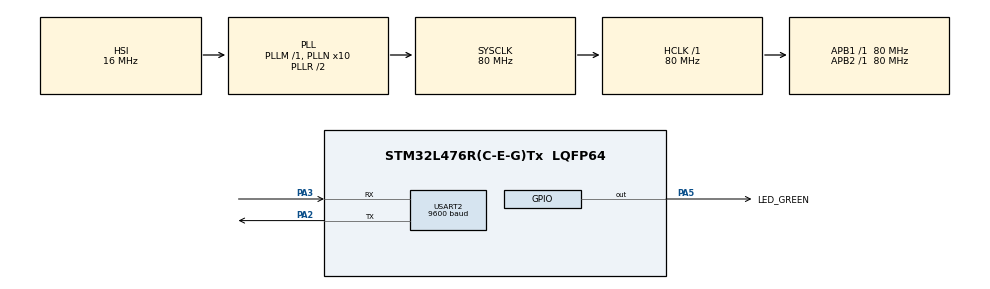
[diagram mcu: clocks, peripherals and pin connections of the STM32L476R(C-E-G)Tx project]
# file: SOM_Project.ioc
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ADC1.Channel-0\#ChannelRegularConversion=ADC_CHANNEL_TEMPSENSOR
ADC1.NbrOfConversionFlag=1
ADC1.OffsetNumber-0\#ChannelRegularConversion=ADC_OFFSET_NONE
ADC1.Rank-0\#ChannelRegularConversion=1
ADC1.SamplingTime-0\#ChannelRegularConversion=ADC_SAMPLETIME_2CYCLES_5
ADC1.master=1
FREERTOS.Queues01=ledCmd,4,Command_t,0,Dynamic,NULL,NULL;adcAnalyzer,16,uint16_t,0,Dynamic,NULL,NULL;adcAlert,16,uint16_t,0,Dynamic,NULL,NULL;uartTx,16,uint8_t,0,Dynamic,NULL,NULL
FREERTOS.Tasks01=UartTask,24,256,StartUartTask,Default,NULL,Dynamic,NULL,NULL;LedTask,8,128,StartLedTask,Default,NULL,Dynamic,NULL,NULL;ADCSampler,8,256,StartADCSampler,Default,NULL,Dynamic,NULL,NULL;DataAnalyzer,8,256,StartDataAnalyzer,Default,NULL,Dynamic,NULL,NULL;AlertMonitor,8,256,StartAlertMonitor,Default,NULL,Dynamic,NULL,NULL
FREERTOS.configTOTAL_HEAP_SIZE=6800
FREERTOS.configUSE_NEWLIB_REENTRANT=1
FREERTOS.configUSE_PREEMPTION=1
Mcu.Family=STM32L4
Mcu.Name=STM32L476R(C-E-G)Tx
Mcu.Package=LQFP64
NVIC.PriorityGroup=NVIC_PRIORITYGROUP_4
NVIC.TIM5_IRQn=true\:15\:0\:false\:false\:true\:false\:false\:true\:true
NVIC.TimeBase=TIM5_IRQn
NVIC.TimeBaseIP=TIM5
NVIC.USART2_IRQn=true\:5\:0\:false\:false\:true\:true\:true\:true\:true
PA13\ (JTMS-SWDIO).Mode=Serial_Wire
PA13\ (JTMS-SWDIO).Signal=SYS_JTMS-SWDIO
PA14\ (JTCK-SWCLK).Mode=Serial_Wire
PA14\ (JTCK-SWCLK).Signal=SYS_JTCK-SWCLK
PA2.Mode=Asynchronous
PA2.Signal=USART2_TX
PA3.Mode=Asynchronous
PA3.Signal=USART2_RX
PA5.GPIO_Label=LED_GREEN
PA5.Signal=GPIO_Output
ProjectManager.HeapSize=0x200
ProjectManager.StackSize=0x400
ProjectManager.TargetToolchain=STM32CubeIDE
RCC.ADCFreq_Value=64000000
RCC.AHBFreq_Value=80000000
RCC.APB1Freq_Value=80000000
RCC.APB1TimFreq_Value=80000000
RCC.APB2Freq_Value=80000000
RCC.APB2TimFreq_Value=80000000
RCC.CortexFreq_Value=80000000
RCC.HCLKFreq_Value=80000000
RCC.HSE_VALUE=8000000
RCC.HSI_VALUE=16000000
RCC.LSE_VALUE=32768
RCC.MSI_VALUE=4000000
RCC.PLLN=10
RCC.PLLSourceVirtual=RCC_PLLSOURCE_HSI
RCC.PREFETCH_ENABLE=1
RCC.SYSCLKFreq_VALUE=80000000
RCC.SYSCLKSource=RCC_SYSCLKSOURCE_PLLCLK
RCC.USBFreq_Value=64000000
RCC.VCOOutputFreq_Value=160000000
USART2.BaudRate=9600
USART2.VirtualMode-Asynchronous=VM_ASYNC
VP_ADC1_TempSens_Input.Mode=IN-TempSens
VP_FREERTOS_VS_CMSIS_V2.Mode=CMSIS_V2
VP_SYS_VS_tim5.Mode=TIM5
board=NUCLEO-L476RG

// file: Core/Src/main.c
/* USER CODE BEGIN Header */
/* USER CODE END Header */
#include "main.h"
#include "cmsis_os.h"

/* USER CODE BEGIN Includes */
#include <stdio.h>
#include <string.h>
#include <stdlib.h>
/* USER CODE END Includes */

/* USER CODE BEGIN PTD */
typedef enum {
    CMD_NONE,
    CMD_START_LED,
    CMD_STOP_LED,
} Command_t;

typedef enum {
    ANALYZER_OFF,
    ANALYZER_AVG,
    ANALYZER_MAX,
    ANALYZER_MIN
} AnalyzerMode_t;

/* USER CODE END PTD */

/* USER CODE BEGIN PD */

#define UART_BUFFER_SIZE     20
#define UART_RESPONSE_SIZE   512
#define MAX_SAMPLES          100

/* USER CODE END PD */

ADC_HandleTypeDef hadc1;

UART_HandleTypeDef huart2;

/* Definitions for UartTask */
osThreadId_t UartTaskHandle;
const osThreadAttr_t UartTask_attributes = {
  .name = "UartTask",
  .stack_size = 256 * 4,
  .priority = (osPriority_t) osPriorityNormal,
};
/* Definitions for LedTask */
osThreadId_t LedTaskHandle;
const osThreadAttr_t LedTask_attributes = {
  .name = "LedTask",
  .stack_size = 128 * 4,
  .priority = (osPriority_t) osPriorityLow,
};
/* Definitions for ADCSampler */
osThreadId_t ADCSamplerHandle;
const osThreadAttr_t ADCSampler_attributes = {
  .name = "ADCSampler",
  .stack_size = 256 * 4,
  .priority = (osPriority_t) osPriorityLow,
};
/* Definitions for DataAnalyzer */
osThreadId_t DataAnalyzerHandle;
const osThreadAttr_t DataAnalyzer_attributes = {
  .name = "DataAnalyzer",
  .stack_size = 256 * 4,
  .priority = (osPriority_t) osPriorityLow,
};
/* Definitions for AlertMonitor */
osThreadId_t AlertMonitorHandle;
const osThreadAttr_t AlertMonitor_attributes = {
  .name = "AlertMonitor",
  .stack_size = 256 * 4,
  .priority = (osPriority_t) osPriorityLow,
};
/* Definitions for ledCmd */
osMessageQueueId_t ledCmdHandle;
const osMessageQueueAttr_t ledCmd_attributes = {
  .name = "ledCmd"
};
/* Definitions for adcAnalyzer */
osMessageQueueId_t adcAnalyzerHandle;
const osMessageQueueAttr_t adcAnalyzer_attributes = {
  .name = "adcAnalyzer"
};
/* Definitions for adcAlert */
osMessageQueueId_t adcAlertHandle;
const osMessageQueueAttr_t adcAlert_attributes = {
  .name = "adcAlert"
};
/* Definitions for uartTx */
osMessageQueueId_t uartTxHandle;
const osMessageQueueAttr_t uartTx_attributes = {
  .name = "uartTx"
};
/* USER CODE BEGIN PV */
volatile uint16_t adc_sample_period = 1000;
volatile uint16_t alert_threshold = 1500;
volatile AnalyzerMode_t analyzer_mode = ANALYZER_OFF;
volatile uint16_t sample_count = 10;
volatile uint8_t alert_active = 0;
uint8_t rx_char;

volatile uint8_t g_rx_buffer[UART_BUFFER_SIZE];
volatile uint16_t g_rx_idx = 0;

const char welcome_msg[] =
	      "\r\n"
	      "***************************************\r\n"
	      " Witaj w programie przygotowanym na \r\n"
	      " projekt z FreeRTOS\r\n"
	      "***************************************\r\n"
	      "Uwaga: Mozna usuwac znaki w terminalu\r\n"
	      "Dostepne polecenia:\r\n"
	      "1. LED: START LED, STOP LED\r\n"
	      "2. ADC: SET PERIOD <ms>, GET PERIOD, GET ADC\r\n"
		  "3. Alert: SET ALERT <value>, GET ALERT\r\n"
	      "4. Analyzer: START ANALYSIS, STOP ANALYSIS, SET ANALYSIS AVG/MAX/MIN, GET ANALYSIS, SET SAMPLES <value>\r\n"
		  "5. HELP\r\n"
	      "6. EXIT\r\n"
	      "***************************************\r\n"
	      "> ";

const char help[] =
	      "\r\n"
	      "***************************************\r\n"
	      " Witaj w programie przygotowanym na \r\n"
	      " projekt z FreeRTOS\r\n"
	      "***************************************\r\n"
	      "Uwaga: Mozna usuwac znaki w terminalu\r\n"
	      "Dostepne polecenia:\r\n"
	      "1. LED: START LED, STOP LED\r\n"
	      "2. ADC: SET PERIOD <ms>, GET PERIOD, GET ADC\r\n"
		  "3. Alert: SET ALERT <value>, GET ALERT\r\n"
	      "4. Analyzer: START ANALYSIS, STOP ANALYSIS, SET ANALYSIS AVG/MAX/MIN, GET ANALYSIS, SET SAMPLES <value>\r\n"
		  "5. HELP\r\n"
	      "6. EXIT\r\n"
	      "***************************************";
/* USER CODE END PV */

void SystemClock_Config(void);
static void MX_GPIO_Init(void);
static void MX_USART2_UART_Init(void);
static void MX_ADC1_Init(void);
void StartUartTask(void *argument);
void StartLedTask(void *argument);
void StartADCSampler(void *argument);
void StartDataAnalyzer(void *argument);
void StartAlertMonitor(void *argument);

/* USER CODE BEGIN PFP */

char* CommandHandler_Parse(char* command);
/* USER CODE END PFP */

/* USER CODE BEGIN 0 */
int __io_putchar(int ch)
{
    HAL_UART_Transmit(&huart2, (uint8_t*)&ch, 1, HAL_MAX_DELAY);
    return 1;
}

// Odbiór pojedynczego znaku przez przerwanie
void HAL_UART_RxCpltCallback(UART_HandleTypeDef *huart)
{

   if(huart->Instance == USART2){
	osMessageQueuePut(uartTxHandle, &rx_char, 0, 0);
	HAL_UART_Receive_IT(&huart2, &rx_char, 1);

   }
}

void uart_print_with_prompt(const char* msg)
{
    // ANSI: \033[2K czyści całą linię, \r ustawia na początek linii
    const char clear_line[] = "\033[2K\r";
    HAL_UART_Transmit(&huart2, (uint8_t*)clear_line, strlen(clear_line), HAL_MAX_DELAY);

    // Wypisz wynik analizy (np. "AVG: 1234\r\n")
    HAL_UART_Transmit(&huart2, (uint8_t*)msg, strlen(msg), HAL_MAX_DELAY);

    // Nowa linia prompta i ponownie dotychczas wpisany tekst
    HAL_UART_Transmit(&huart2, (uint8_t*)"\r\n> ", 5, HAL_MAX_DELAY);
    if(g_rx_idx > 0) {
        HAL_UART_Transmit(&huart2, (uint8_t*)g_rx_buffer, g_rx_idx, HAL_MAX_DELAY);
    }
}

/* USER CODE END 0 */

int main(void)
{

  /* MCU Configuration--------------------------------------------------------*/

  /* Reset of all peripherals, Initializes the Flash interface and the Systick. */
  HAL_Init();

  /* Configure the system clock */
  SystemClock_Config();

  /* Initialize all configured peripherals */
  MX_GPIO_Init();
  MX_USART2_UART_Init();
  MX_ADC1_Init();
  /* USER CODE BEGIN 2 */

  HAL_UART_Receive_IT(&huart2, &rx_char, 1);
  HAL_ADCEx_Calibration_Start(&hadc1, ADC_SINGLE_ENDED);
  /* USER CODE END 2 */

  /* Init scheduler */
  osKernelInitialize();

  /* Create the queue(s) */
  /* creation of ledCmd */
  ledCmdHandle = osMessageQueueNew (4, sizeof(Command_t), &ledCmd_attributes);

  /* creation of adcAnalyzer */
  adcAnalyzerHandle = osMessageQueueNew (16, sizeof(uint16_t), &adcAnalyzer_attributes);

  /* creation of adcAlert */
  adcAlertHandle = osMessageQueueNew (16, sizeof(uint16_t), &adcAlert_attributes);

  /* creation of uartTx */
  uartTxHandle = osMessageQueueNew (16, sizeof(uint8_t), &uartTx_attributes);

  /* Create the thread(s) */
  /* creation of UartTask */
  UartTaskHandle = osThreadNew(StartUartTask, NULL, &UartTask_attributes);

  /* creation of LedTask */
  LedTaskHandle = osThreadNew(StartLedTask, NULL, &LedTask_attributes);

  /* creation of ADCSampler */
  ADCSamplerHandle = osThreadNew(StartADCSampler, NULL, &ADCSampler_attributes);

  /* creation of DataAnalyzer */
  DataAnalyzerHandle = osThreadNew(StartDataAnalyzer, NULL, &DataAnalyzer_attributes);

  /* creation of AlertMonitor */
  AlertMonitorHandle = osThreadNew(StartAlertMonitor, NULL, &AlertMonitor_attributes);

  /* Start scheduler */
  osKernelStart();

  /* We should never get here as control is now taken by the scheduler */

  /* Infinite loop */

}

void SystemClock_Config(void)
{
  RCC_OscInitTypeDef RCC_OscInitStruct = {0};
  RCC_ClkInitTypeDef RCC_ClkInitStruct = {0};

  /** Configure the main internal regulator output voltage
  */
  if (HAL_PWREx_ControlVoltageScaling(PWR_REGULATOR_VOLTAGE_SCALE1) != HAL_OK)
  {
    Error_Handler();
  }

  /** Initializes the RCC Oscillators according to the specified parameters
  * in the RCC_OscInitTypeDef structure.
  */
  RCC_OscInitStruct.OscillatorType = RCC_OSCILLATORTYPE_HSI;
  RCC_OscInitStruct.HSIState = RCC_HSI_ON;
  RCC_OscInitStruct.HSICalibrationValue = RCC_HSICALIBRATION_DEFAULT;
  RCC_OscInitStruct.PLL.PLLState = RCC_PLL_ON;
  RCC_OscInitStruct.PLL.PLLSource = RCC_PLLSOURCE_HSI;
  RCC_OscInitStruct.PLL.PLLM = 1;
  RCC_OscInitStruct.PLL.PLLN = 10;
  RCC_OscInitStruct.PLL.PLLP = RCC_PLLP_DIV7;
  RCC_OscInitStruct.PLL.PLLQ = RCC_PLLQ_DIV2;
  RCC_OscInitStruct.PLL.PLLR = RCC_PLLR_DIV2;
  if (HAL_RCC_OscConfig(&RCC_OscInitStruct) != HAL_OK)
  {
    Error_Handler();
  }

  /** Initializes the CPU, AHB and APB buses clocks
  */
  RCC_ClkInitStruct.ClockType = RCC_CLOCKTYPE_HCLK|RCC_CLOCKTYPE_SYSCLK
                              |RCC_CLOCKTYPE_PCLK1|RCC_CLOCKTYPE_PCLK2;
  RCC_ClkInitStruct.SYSCLKSource = RCC_SYSCLKSOURCE_PLLCLK;
  RCC_ClkInitStruct.AHBCLKDivider = RCC_SYSCLK_DIV1;
  RCC_ClkInitStruct.APB1CLKDivider = RCC_HCLK_DIV1;
  RCC_ClkInitStruct.APB2CLKDivider = RCC_HCLK_DIV1;

  if (HAL_RCC_ClockConfig(&RCC_ClkInitStruct, FLASH_LATENCY_4) != HAL_OK)
  {
    Error_Handler();
  }
}

static void MX_ADC1_Init(void)
{

  ADC_MultiModeTypeDef multimode = {0};
  ADC_ChannelConfTypeDef sConfig = {0};

  /** Common config
  */
  hadc1.Instance = ADC1;
  hadc1.Init.ClockPrescaler = ADC_CLOCK_ASYNC_DIV1;
  hadc1.Init.Resolution = ADC_RESOLUTION_12B;
  hadc1.Init.DataAlign = ADC_DATAALIGN_RIGHT;
  hadc1.Init.ScanConvMode = ADC_SCAN_DISABLE;
  hadc1.Init.EOCSelection = ADC_EOC_SINGLE_CONV;
  hadc1.Init.LowPowerAutoWait = DISABLE;
  hadc1.Init.ContinuousConvMode = DISABLE;
  hadc1.Init.NbrOfConversion = 1;
  hadc1.Init.DiscontinuousConvMode = DISABLE;
  hadc1.Init.ExternalTrigConv = ADC_SOFTWARE_START;
  hadc1.Init.ExternalTrigConvEdge = ADC_EXTERNALTRIGCONVEDGE_NONE;
  hadc1.Init.DMAContinuousRequests = DISABLE;
  hadc1.Init.Overrun = ADC_OVR_DATA_PRESERVED;
  hadc1.Init.OversamplingMode = DISABLE;
  if (HAL_ADC_Init(&hadc1) != HAL_OK)
  {
    Error_Handler();
  }

  /** Configure the ADC multi-mode
  */
  multimode.Mode = ADC_MODE_INDEPENDENT;
  if (HAL_ADCEx_MultiModeConfigChannel(&hadc1, &multimode) != HAL_OK)
  {
    Error_Handler();
  }

  /** Configure Regular Channel
  */
  sConfig.Channel = ADC_CHANNEL_TEMPSENSOR;
  sConfig.Rank = ADC_REGULAR_RANK_1;
  sConfig.SamplingTime = ADC_SAMPLETIME_247CYCLES_5;
  sConfig.SingleDiff = ADC_SINGLE_ENDED;
  sConfig.OffsetNumber = ADC_OFFSET_NONE;
  sConfig.Offset = 0;
  if (HAL_ADC_ConfigChannel(&hadc1, &sConfig) != HAL_OK)
  {
    Error_Handler();
  }

}

static void MX_USART2_UART_Init(void)
{

  huart2.Instance = USART2;
  huart2.Init.BaudRate = 9600;
  huart2.Init.WordLength = UART_WORDLENGTH_8B;
  huart2.Init.StopBits = UART_STOPBITS_1;
  huart2.Init.Parity = UART_PARITY_NONE;
  huart2.Init.Mode = UART_MODE_TX_RX;
  huart2.Init.HwFlowCtl = UART_HWCONTROL_NONE;
  huart2.Init.OverSampling = UART_OVERSAMPLING_16;
  huart2.Init.OneBitSampling = UART_ONE_BIT_SAMPLE_DISABLE;
  huart2.AdvancedInit.AdvFeatureInit = UART_ADVFEATURE_NO_INIT;
  if (HAL_UART_Init(&huart2) != HAL_OK)
  {
    Error_Handler();
  }

}

static void MX_GPIO_Init(void)
{
  GPIO_InitTypeDef GPIO_InitStruct = {0};

  /* GPIO Ports Clock Enable */
  __HAL_RCC_GPIOA_CLK_ENABLE();

  /*Configure GPIO pin Output Level */
  HAL_GPIO_WritePin(LED_GREEN_GPIO_Port, LED_GREEN_Pin, GPIO_PIN_RESET);

  /*Configure GPIO pin : LED_GREEN_Pin */
  GPIO_InitStruct.Pin = LED_GREEN_Pin;
  GPIO_InitStruct.Mode = GPIO_MODE_OUTPUT_PP;
  GPIO_InitStruct.Pull = GPIO_NOPULL;
  GPIO_InitStruct.Speed = GPIO_SPEED_FREQ_LOW;
  HAL_GPIO_Init(LED_GREEN_GPIO_Port, &GPIO_InitStruct);

}

/* USER CODE BEGIN 4 */

char* CommandHandler_Parse(char* command) {
    static char response[UART_RESPONSE_SIZE];

    char* token1 = strtok(command," ");
    char* token2 = strtok(NULL," ");
    char* token3 = strtok(NULL," ");

    if (token1 == NULL) {
        snprintf(response, sizeof(response), "ERROR: Empty command");
        return response;
    }

    /* LED Commands */
    if (strcmp(token1, "START") == 0 && token2 && strcmp(token2,"LED") == 0){
            Command_t cmd = CMD_START_LED;
            osMessageQueuePut(ledCmdHandle, &cmd, 0, 0);
            snprintf(response, sizeof(response), "LED blinking started");
        }else if(strcmp(token1,"STOP") == 0 && token2 && strcmp(token2, "LED") == 0){
            Command_t cmd = CMD_STOP_LED;
            osMessageQueuePut(ledCmdHandle, &cmd, 0, 0);
            snprintf(response,sizeof(response), "LED stopped");
        }
    /* ADC Commands */
    else if (strcmp(token1, "GET") == 0 && token2 && strcmp(token2,"ADC") == 0){
    	HAL_ADC_Start(&hadc1);
    	if(HAL_ADC_PollForConversion(&hadc1, HAL_MAX_DELAY) == HAL_OK){
    		uint16_t adc_value = HAL_ADC_GetValue(&hadc1);
    		snprintf(response,sizeof(response),"ADC: %u",adc_value);
    	}else{
    		snprintf(response,sizeof(response),"ADC Error\r\n");
    	}
    }
    else if(strcmp(token1, "GET") == 0 && token2 && strcmp(token2,"PERIOD") == 0){
        		snprintf(response, sizeof(response), "Current ADC period: %ums", adc_sample_period);
        	}
    else if (strcmp(token1, "SET") == 0 && token2 && strcmp(token2,"PERIOD") == 0 && token3){
       uint16_t new_period = atoi(token3);
       if(new_period >= 10 && new_period <= 5000){
    	   adc_sample_period = new_period;
    	   snprintf(response, sizeof(response),"ADC period set to %ums",new_period);
       }else{
    	   snprintf(response,sizeof(response),"ERROR: Period must be 10-5000ms");
       }
    }
    /* Alert Commands */
    else if(strcmp(token1,"SET") == 0 && token2 && strcmp(token2,"ALERT") == 0 && token3){
       alert_threshold = atoi(token3);
       snprintf(response,sizeof(response), "Alert threshold set to %u",alert_threshold);
    }else if(strcmp(token1,"GET") == 0 && token2 && strcmp(token2,"ALERT") == 0){
    	snprintf(response,sizeof(response), "Alert threshold set to %u",alert_threshold);
    }
    /* Analyzer Commands */
    else if (strcmp(token1,"START") == 0 && token2 && strcmp(token2,"ANALYSIS") == 0){
        analyzer_mode = ANALYZER_AVG;  // Default mode
        snprintf(response, sizeof(response), "Data analysis started (AVG mode)");
    }
    else if (strcmp(token1,"STOP") == 0 && token2 && strcmp(token2,"ANALYSIS") == 0){
        analyzer_mode = ANALYZER_OFF;
        snprintf(response, sizeof(response), "Data analysis stopped");
    }
    else if (strcmp(token1,"SET") == 0 && token2 && strcmp(token2,"ANALYSIS") == 0 && token3){
    	if(strcmp(token3,"AVG") == 0){
    		analyzer_mode = ANALYZER_AVG;
    		snprintf(response, sizeof(response), "Analysis mode set to AVG");
    	}else if(strcmp(token3,"MAX") == 0){
    		analyzer_mode = ANALYZER_MAX;
    		snprintf(response, sizeof(response), "Analysis mode set to MAX");
    	}else if(strcmp(token3,"MIN") == 0){
    		analyzer_mode = ANALYZER_MIN;
    		snprintf(response, sizeof(response), "Analysis mode set to MIN");
    	}else{
    		snprintf(response,sizeof(response), "ERROR: Usage: SET ANALYSIS <AVG|MAX|MIN>");
    	}
    }
    else if(strcmp(token1,"GET") == 0 && token2 && strcmp(token2,"ANALYSIS") == 0){
    	const char* mode_str = "UNKNOWN";
    	switch(analyzer_mode){
    		case ANALYZER_AVG: mode_str = "AVG"; break;
    		case ANALYZER_MAX: mode_str = "MAX"; break;
    		case ANALYZER_MIN: mode_str = "MIN"; break;
    		case ANALYZER_OFF: mode_str = "OFF"; break;
    	}
    	snprintf(response, sizeof(response), "Curremt analysis mode: %s",mode_str);
    }
    else if(strcmp(token1,"SET") == 0 && token2 && strcmp(token2, "SAMPLES") == 0 && token3){
    	uint16_t new_count = atoi(token3);
    	if(new_count > 0 && new_count <= MAX_SAMPLES){
    		sample_count = new_count;
    		snprintf(response, sizeof(response), "Sample count set to %u", new_count);
    	}else{
    		snprintf(response, sizeof(response), "ERROR: Samples must be 1-%u",MAX_SAMPLES);
    	}
    }else if(strcmp(token1,"EXIT") == 0){
    	snprintf(response, sizeof(response), "The End");
    	HAL_GPIO_WritePin(LED_GREEN_GPIO_Port, LED_GREEN_Pin, GPIO_PIN_RESET);
    	analyzer_mode = ANALYZER_OFF;
    //	osThreadExit();
    }else if(strcmp(token1,"HELP") == 0){
    	snprintf(response, sizeof(response), "%s", help);
    }
    /* Unknown Command */
    else {
    	snprintf(response, sizeof(response), "ERROR: Unknown command or wrong syntax");
    }

    return response;
}
/* USER CODE END 4 */

void StartUartTask(void *argument)
{
  /* USER CODE BEGIN 5 */
	uint8_t rx_char;
	extern volatile uint8_t g_rx_buffer[UART_BUFFER_SIZE];
	extern volatile uint16_t g_rx_idx;

	HAL_UART_Transmit(&huart2, (uint8_t*)welcome_msg, strlen(welcome_msg), HAL_MAX_DELAY);

	  /* Infinite loop */
	for(;;)
		{
			if (osMessageQueueGet(uartTxHandle, &rx_char, NULL, osWaitForever) == osOK) {
				if (rx_char == '\b' || rx_char == 127) { //Usuwanie znakow z terminala
					if (g_rx_idx > 0) {
						g_rx_idx--;
						HAL_UART_Transmit(&huart2, (uint8_t*)"\b \b", 3, HAL_MAX_DELAY);
					}
					continue;
				}

				if (rx_char != '\r' && rx_char != '\n') {
					HAL_UART_Transmit(&huart2, &rx_char, 1, HAL_MAX_DELAY); //Echo znaku
				}

				if (rx_char == '\n' || rx_char == '\r') {
					 g_rx_buffer[g_rx_idx] = '\0';  // Null-terminate
						char* response = CommandHandler_Parse((char*)g_rx_buffer);
						HAL_UART_Transmit(&huart2, (uint8_t*)"\r\n", 2, HAL_MAX_DELAY);
						HAL_UART_Transmit(&huart2, (uint8_t*)response, strlen(response), HAL_MAX_DELAY);
						HAL_UART_Transmit(&huart2, (uint8_t*)"\r\n> ", 5, HAL_MAX_DELAY);
						g_rx_idx = 0;
				}
				else if (g_rx_idx < UART_BUFFER_SIZE - 1) {
					g_rx_buffer[g_rx_idx++] = rx_char;
				}
				else {
					HAL_UART_Transmit(&huart2, (uint8_t*)"\r\nERROR: Command too long\r\n> ", 28, HAL_MAX_DELAY);
					g_rx_idx = 0;
				}
			}
			osDelay(1);
		}

  /* USER CODE END 5 */
}

void StartLedTask(void *argument)
{
  /* USER CODE BEGIN StartLedTask */
	uint8_t led_state = 0;
	Command_t cmd;
  /* Infinite loop */
  for(;;)
  {
	  if(osMessageQueueGet(ledCmdHandle, &cmd, NULL, 0) == osOK){
	  		if(cmd == CMD_START_LED){
	  			led_state = 1;
	  		}else if(cmd == CMD_STOP_LED){
	  			led_state = 0;
	  		}
	  		}
	  		if (led_state) {
	  			HAL_GPIO_WritePin(LED_GREEN_GPIO_Port, LED_GREEN_Pin, GPIO_PIN_SET);
	  			osDelay(500);
	  			HAL_GPIO_WritePin(LED_GREEN_GPIO_Port, LED_GREEN_Pin, GPIO_PIN_RESET);
	  			osDelay(500);
	  		} else {
	  			osDelay(10);
	  		}
  }
  /* USER CODE END StartLedTask */
}

void StartADCSampler(void *argument)
{
  /* USER CODE BEGIN StartADCSampler */
	uint16_t adc_value = 0;
  /* Infinite loop */
  for(;;)
  {
	HAL_ADC_Start(&hadc1);
	if(HAL_ADC_PollForConversion(&hadc1, HAL_MAX_DELAY) == HAL_OK){
		adc_value = HAL_ADC_GetValue(&hadc1);
		osMessageQueuePut(adcAnalyzerHandle, &adc_value, 0, 0);
		osMessageQueuePut(adcAlertHandle, &adc_value, 0, 0);
	}
    osDelay(adc_sample_period);
  }
  /* USER CODE END StartADCSampler */
}

void StartDataAnalyzer(void *argument)
{
  /* USER CODE BEGIN StartDataAnalyzer */
	uint16_t buffer[MAX_SAMPLES] = {0};
    uint16_t idx = 0;
	uint16_t current_sample_count = sample_count;
  /* Infinite loop */
  for(;;)
  {

		current_sample_count = sample_count; // aktualizacja na bieżąco
		if(osMessageQueueGet(adcAnalyzerHandle, &buffer[idx], NULL, osWaitForever) == osOK){
			if(analyzer_mode != ANALYZER_OFF){
				idx = (idx + 1)%current_sample_count;
				if(idx==0){
					uint32_t sum = 0;
					uint16_t max_val = 0;
					uint16_t min_val = 0xFFFF; //Dzieki temu kazda inna jest mniejsza
					for(int i = 0; i < current_sample_count; i++){
						sum += buffer[i];
						if(buffer[i] > max_val) max_val = buffer[i];
						if(buffer[i] < min_val) min_val = buffer[i];
					}
					char msg[64];
					switch(analyzer_mode){
						case ANALYZER_AVG:
							snprintf(msg, sizeof(msg), "AVG: %lu",sum/current_sample_count);
							break;
						case ANALYZER_MAX:
							snprintf(msg, sizeof(msg), "MAX: %u",max_val);
							break;
						case ANALYZER_MIN:
							snprintf(msg,sizeof(msg),"MIN: %u",min_val);
							break;
						default:
							break;
					}
					uart_print_with_prompt(msg);
				}
			}
		}
		osDelay(1);
  }
  /* USER CODE END StartDataAnalyzer */
}

void StartAlertMonitor(void *argument)
{
  /* USER CODE BEGIN StartAlertMonitor */
	uint16_t adc_value;
  /* Infinite loop */
  for(;;)
  {
	  if(osMessageQueueGet(adcAlertHandle, &adc_value, NULL, osWaitForever) == osOK){
	  			if(adc_value > alert_threshold){
	  				if(!alert_active){
	  					char alert_msg[64];
	  					snprintf(alert_msg, sizeof(alert_msg),"!!! ALERT: Value %u above limit !!!",adc_value);
	  					uart_print_with_prompt(alert_msg);
	  					alert_active = 1;
	  				}
	  			}else{
	  				alert_active = 0;
	  			}
	  		}
	  		osDelay(1);
  }
  /* USER CODE END StartAlertMonitor */
}

void HAL_TIM_PeriodElapsedCallback(TIM_HandleTypeDef *htim)
{
  if (htim->Instance == TIM5)
  {
    HAL_IncTick();
  }
}

void Error_Handler(void)
{
}
